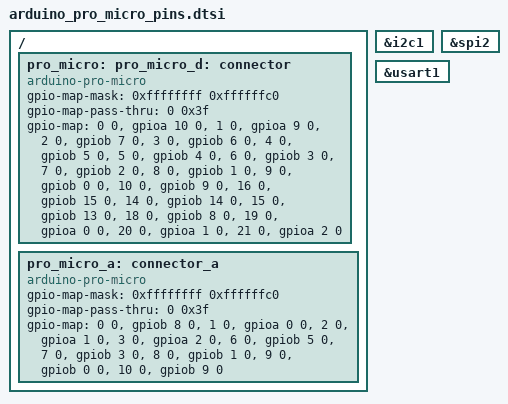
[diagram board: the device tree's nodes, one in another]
/*
 * Copyright (c) 2020 Pete Johanson
 *
 * SPDX-License-Identifier: MIT
 */

/ {
	pro_micro: connector {
		compatible = "arduino-pro-micro";
		#gpio-cells = <2>;
		gpio-map-mask = <0xffffffff 0xffffffc0>;
		gpio-map-pass-thru = <0 0x3f>;
		gpio-map
			= <0 0 &gpioa 10 0>	/* D0 */
			, <1 0 &gpioa 9 0>		/* D1 */
			, <2 0 &gpiob 7 0>		/* D2 */
			, <3 0 &gpiob 6 0>		/* D3 */
			, <4 0 &gpiob 5 0>		/* D4/A6 */
			, <5 0 &gpiob 4 0>		/* D5 */
			, <6 0 &gpiob 3 0>		/* D6/A7 */
			, <7 0 &gpiob 2 0>		/* D7 */
			, <8 0 &gpiob 1 0>		/* D8/A8 */
			, <9 0 &gpiob 0 0>		/* D9/A9 */
			, <10 0 &gpiob 9 0>		/* D10/A10 */
			, <16 0 &gpiob 15 0>	/* D16 */
			, <14 0 &gpiob 14 0>	/* D14 */
			, <15 0 &gpiob 13 0>	/* D15 */
			, <18 0 &gpiob 8 0>	/* D18/A0 */
			, <19 0 &gpioa 0 0>	/* D19/A1 */
			, <20 0 &gpioa 1 0>	/* D20/A2 */
			, <21 0 &gpioa 2 0>	/* D21/A3 */
			;
	};

	pro_micro_a: connector_a {
		compatible = "arduino-pro-micro";
		#gpio-cells = <2>;
		gpio-map-mask = <0xffffffff 0xffffffc0>;
		gpio-map-pass-thru = <0 0x3f>;
		gpio-map
			= <0 0 &gpiob 8 0>	/* D18/A0 */
			, <1 0 &gpioa 0 0>	/* D19/A1 */
			, <2 0 &gpioa 1 0>	/* D20/A2 */
			, <3 0 &gpioa 2 0>	/* D21/A3 */
			, <6 0 &gpiob 5 0>	/* D4/A6 */
			, <7 0 &gpiob 3 0>	/* D6/A7 */
			, <8 0 &gpiob 1 0>	/* D8/A8 */
			, <9 0 &gpiob 0 0>	/* D9/A9 */
			, <10 0 &gpiob 9 0>	/* D10/A10 */
			;
	};
};

pro_micro_d: &pro_micro {};
pro_micro_i2c: &i2c1 {};
pro_micro_spi: &spi2 {};
pro_micro_serial: &usart1 {};
